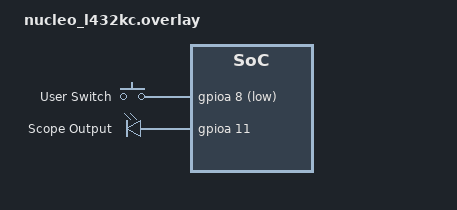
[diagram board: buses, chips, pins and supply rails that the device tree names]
/ {
	aliases {

		sw-input = &button_d9; /* this is my input because i called it that*/

		wave-out = &pin_d10; /* same sh*t */
	};

	gpio_keys {
		compatible = "gpio-keys";

		button_d9: button_d9 {
			gpios = <&gpioa 8 (GPIO_PULL_UP | GPIO_ACTIVE_LOW)>;
			label = "User Switch";
		};
	};

	/* def outs */
	leds {
		compatible = "gpio-leds";
		
		pin_d10: scope_out {
			gpios = <&gpioa 11 GPIO_ACTIVE_HIGH>;
			label = "Scope Output";
		};
	};
};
